# S6E1C1xB register map
Vendor: Cypress; File version: 2.0
CPU: CM0PLUS r0p1, little endian, no MPU, no FPU, 2 interrupt priority bits
Registers are 32-bit, read-write, reset 0x0 unless marked. A register's access mark holds for its fields unless they carry their own. Offsets are from the block's base; [hi:lo] are bit positions; {n}, {i} and the like mark numbered series.

## MFSI2S0 — I2S0 Registers
Base 0x4003CA00
Same registers: MFSI2S1 0x4003CA80
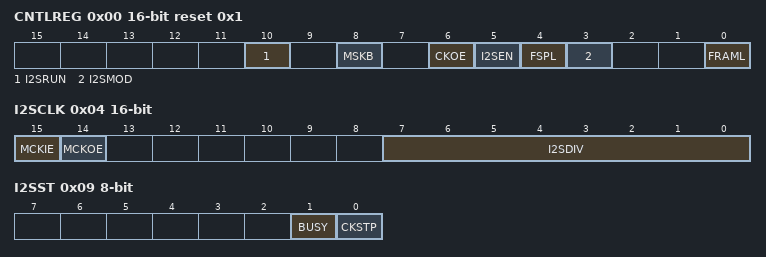
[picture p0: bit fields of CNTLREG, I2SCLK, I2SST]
0x00 CNTLREG 16-bit reset 0x1 — Control Register
  [10] I2SRUN — I2S clock generate enable bit
  [8] MSKB — Mask bit output bit
  [6] CKOE — I2SCK and I2SWS output enable bit
  [5] I2SEN — I2S mode enable bit
  [4] FSPL — I2SWS polarity set bit
  [3] I2SMOD — I2S mode select bit
  [0] FRAML — Frame length select bit
0x04 I2SCLK 16-bit — I2S Clock Register
  [15] MCKIE — Main clock input enable bit
  [14] MCKOE — Main clock output enable bit
  [7:0] I2SDIV — I2S clock division set bit
0x08 I2SRST 8-bit wo — I2S Reset Register
  [7:0] I2SRST — I2S software reset bit
0x09 I2SST 8-bit ro — I2S Status Register
  [1] BUSY — Bus busy indication for transmit bit
  [0] CKSTP — Clock stop indication bit

## DSTC — DSTC registers
Base 0x40061000
0x00 DESTP — Descriptor top address Register
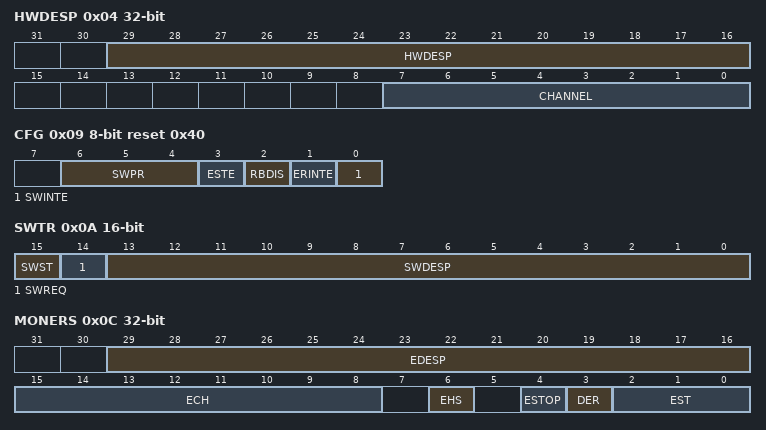
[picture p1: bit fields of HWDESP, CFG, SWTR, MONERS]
0x04 HWDESP — Hardware DES pointer Register
  [29:16] HWDESP, [7:0] CHANNEL
0x08 CMD 8-bit reset 0x1 — Command Register
0x09 CFG 8-bit reset 0x40 — Configuration Register
  [6:4] SWPR — Software transfer priority
  [3] ESTE — Error stop enable
  [2] RBDIS — Read skip buffer disable
  [1] ERINTE — Error interrupt enable
  [0] SWINTE — Software interrupt enable
0x0A SWTR 16-bit — Software trigger Register
  [15] SWST ro — Software status
  [14] SWREQ ro — Software request
  [13:0] SWDESP — Software DES pointer
0x0C MONERS — Transfer Error Status Monitor Register
  [29:16] EDESP ro — Error DES pointer
  [15:8] ECH ro — Error hardware channel
  [6] EHS ro — Error hardware software
  [4] ESTOP ro — Error stop
  [3] DER ro — Double error
  [2:0] EST ro — Error status
0x10 DREQENB0 — DMA request enable Register 0
0x14 DREQENB1 — DMA request enable Register 1
0x30 HWINT0 — Hardware transfer interrupt Register 0
0x34 HWINT1 — Hardware transfer interrupt Register 1
0x50 HWINTCLR0 — Hardware transfer interrupt clear Register 0
0x54 HWINTCLR1 — Hardware transfer interrupt clear Register 1
0x70 DQMSK0 — DMA request mask Register 0
0x74 DQMSK1 — DMA request mask Register 1
0x90 DQMSKCLR0 — DMA request mask clear Register 0
0x94 DQMSKCLR1 — DMA request mask clear Register 1

## MTB_DWT — Micro Trace Buffer Data Watchpoint and Trace Registers
Base 0xF0001000
0x00 CMP_ADDR_START — MTB_DWT Address Compare Start trace Register
  [31:0] ADCMP_STA — MTB_DWT address comparison start trace bits
0x04 CMP_DATA_START — MTB_DWT Data Compare Start trace Register
  [31:0] DTCMP_STA — MTB_DWT data comparison start trace bits
0x08 CMP_MASK_START — MTB_DWT Mask Data Compare Start Trace Register
  [31:0] MSK_STA — MTB_DWT data compare start trace register mask bits
0x10 CMP_ADDR_STOP — MTB_DWT Address Compare Stop trace Register
  [31:0] ADCMP_STO — MTB_DWT address comparison stop trace bits
0x14 CMP_DATA_STOP — MTB_DWT Data Compare Stop trace Register
  [31:0] DTCMP_STO — MTB_DWT data comparison stop trace bits
0x18 CMP_MASK_STOP — MTB_DWT Mask Data Compare Stop Trace Register
  [31:0] MSK_STO — MTB_DWT data compare stop trace register mask bits
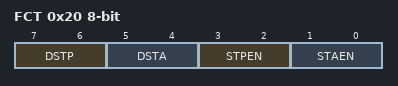
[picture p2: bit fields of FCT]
0x20 FCT 8-bit — MTB_DWT Function Register
  [7:6] DSTP — Data size stop bits
  [5:4] DSTA — Data size start bits
  [3:2] STPEN — Enable MTB_DWT stop MTB function bits
  [1:0] STAEN — Enable MTB_DWT start MTB function bits
{0xFC0+4i} PID{i} ro (i=4..7) — Peripheral ID{i} Register
  [31:0] PERID — Peripheral ID bits
0xFE0 PID0 ro reset 0x16 — Peripheral ID0 Register
  [31:0] PERID — Peripheral ID bits
0xFE4 PID1 ro reset 0x48 — Peripheral ID1 Register
  [31:0] PERID — Peripheral ID bits
0xFE8 PID2 ro reset 0x8 — Peripheral ID2 Register
  [31:0] PERID — Peripheral ID bits
0xFEC PID3 ro — Peripheral ID3 Register
  [31:0] PERID — Peripheral ID bits
0xFF0 CID0 ro reset 0xD — Component ID0 Register
  [31:0] CPNTID — Component ID bits
0xFF4 CID1 ro reset 0x90 — Component ID1 Register
  [31:0] CPNTID — Component ID bits
0xFF8 CID2 ro reset 0x5 — Component ID2 Register
  [31:0] CPNTID — Component ID bits
0xFFC CID3 ro reset 0xB1 — Component ID3 Register
  [31:0] CPNTID — Component ID bits

## FASTIO — Fast GPIO Registers
Base 0xF8000000
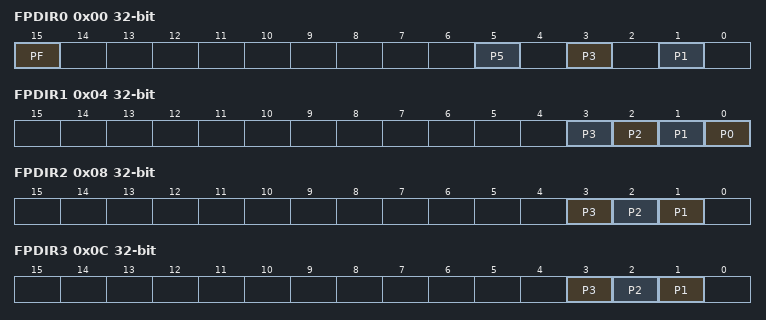
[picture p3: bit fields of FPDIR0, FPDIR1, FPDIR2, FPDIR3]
0x00 FPDIR0 ro — Fast GPIO Input Data Register 0
  [15] PF rw — Bit15 of FPDIR0
  [5] P5 rw — Bit5 of FPDIR0
  [3] P3 rw — Bit3 of FPDIR0
  [1] P1 rw — Bit1 of FPDIR0
0x04 FPDIR1 ro — Fast GPIO Input Data Register 1
  [n] P{n} rw (n=0..3) — Bit{n} of FPDIR1
0x08 FPDIR2 ro — Fast GPIO Input Data Register 2
  [3] P3 rw — Bit3 of FPDIR2
  [2] P2 rw — Bit2 of FPDIR2
  [1] P1 rw — Bit1 of FPDIR2
0x0C FPDIR3 ro — Fast GPIO Input Data Register 3
  [3] P3 rw — Bit3 of FPDIR3
  [2] P2 rw — Bit2 of FPDIR3
  [1] P1 rw — Bit1 of FPDIR3
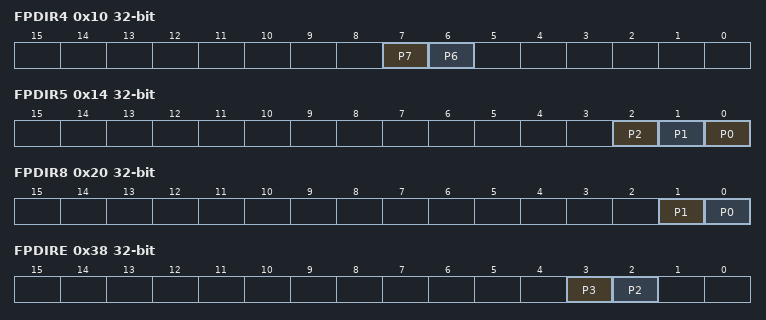
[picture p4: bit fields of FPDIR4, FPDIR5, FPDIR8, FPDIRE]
0x10 FPDIR4 ro — Fast GPIO Input Data Register 4
  [7] P7 rw — Bit7 of FPDIR4
  [6] P6 rw — Bit6 of FPDIR4
0x14 FPDIR5 ro — Fast GPIO Input Data Register 5
  [2] P2 rw — Bit2 of FPDIR5
  [1] P1 rw — Bit1 of FPDIR5
  [0] P0 rw — Bit0 of FPDIR5
0x18 FPDIR6 ro — Fast GPIO Input Data Register 6
  [0] P0 rw — Bit0 of FPDIR6
0x1C FPDIR7 ro reset not defined — Fast GPIO Input Data Register 7
0x20 FPDIR8 ro — Fast GPIO Input Data Register 8
  [1] P1 rw — Bit1 of FPDIR8
  [0] P0 rw — Bit0 of FPDIR8
0x24 FPDIR9 ro reset not defined — Fast GPIO Input Data Register 9
0x28 FPDIRA ro reset not defined — Fast GPIO Input Data Register A
0x2C FPDIRB ro reset not defined — Fast GPIO Input Data Register B
0x30 FPDIRC ro reset not defined — Fast GPIO Input Data Register C
0x34 FPDIRD ro reset not defined — Fast GPIO Input Data Register D
0x38 FPDIRE ro — Fast GPIO Input Data Register E
  [3] P3 rw — Bit3 of FPDIRE
  [2] P2 rw — Bit2 of FPDIRE
0x3C FPDIRF ro reset not defined — Fast GPIO Input Data Register F
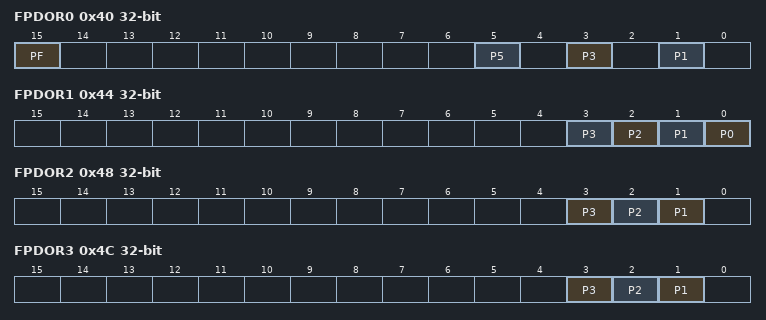
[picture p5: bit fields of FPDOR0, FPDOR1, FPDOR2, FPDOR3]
0x40 FPDOR0 — Fast GPIO Output Data Register 0
  [15] PF — Bit15 of FPDOR0
  [5] P5 — Bit5 of FPDOR0
  [3] P3 — Bit3 of FPDOR0
  [1] P1 — Bit1 of FPDOR0
0x44 FPDOR1 — Fast GPIO Output Data Register 1
  [n] P{n} (n=0..3) — Bit{n} of FPDOR1
0x48 FPDOR2 — Fast GPIO Output Data Register 2
  [3] P3 — Bit3 of FPDOR2
  [2] P2 — Bit2 of FPDOR2
  [1] P1 — Bit1 of FPDOR2
0x4C FPDOR3 — Fast GPIO Output Data Register 3
  [3] P3 — Bit3 of FPDOR3
  [2] P2 — Bit2 of FPDOR3
  [1] P1 — Bit1 of FPDOR3
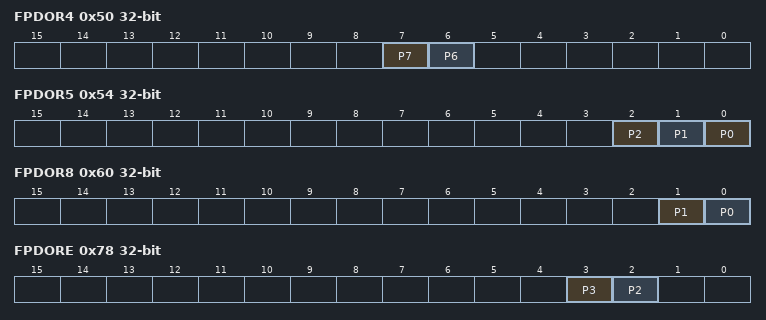
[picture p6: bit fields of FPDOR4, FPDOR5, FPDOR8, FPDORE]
0x50 FPDOR4 — Fast GPIO Output Data Register 4
  [7] P7 — Bit7 of FPDOR4
  [6] P6 — Bit6 of FPDOR4
0x54 FPDOR5 — Fast GPIO Output Data Register 5
  [2] P2 — Bit2 of FPDOR5
  [1] P1 — Bit1 of FPDOR5
  [0] P0 — Bit0 of FPDOR5
0x58 FPDOR6 — Fast GPIO Output Data Register 6
  [0] P0 — Bit0 of FPDOR6
0x5C FPDOR7 reset not defined — Fast GPIO Output Data Register 7
0x60 FPDOR8 — Fast GPIO Output Data Register 8
  [1] P1 — Bit1 of FPDOR8
  [0] P0 — Bit0 of FPDOR8
0x64 FPDOR9 reset not defined — Fast GPIO Output Data Register 9
0x68 FPDORA reset not defined — Fast GPIO Output Data Register A
0x6C FPDORB reset not defined — Fast GPIO Output Data Register B
0x70 FPDORC reset not defined — Fast GPIO Output Data Register C
0x74 FPDORD reset not defined — Fast GPIO Output Data Register D
0x78 FPDORE — Fast GPIO Output Data Register E
  [3] P3 — Bit3 of FPDORE
  [2] P2 — Bit2 of FPDORE
0x7C FPDORF reset not defined — Fast GPIO Output Data Register F
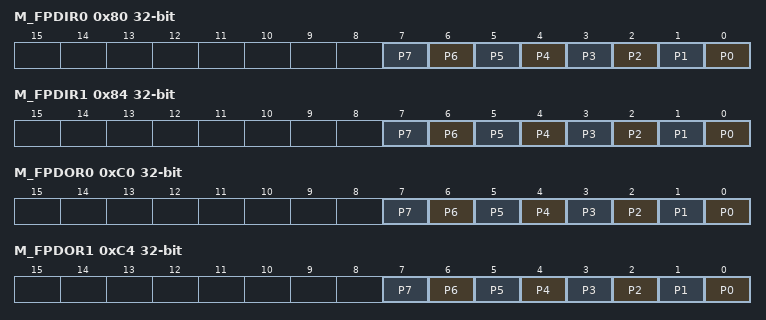
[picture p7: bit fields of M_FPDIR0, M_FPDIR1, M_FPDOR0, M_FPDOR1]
0x80 M_FPDIR0 ro — Mirror Fast GPIO Input Data Register 0
  [n] P{n} rw (n=0..7) — Bit{n} of M_FPDIR0
0x84 M_FPDIR1 ro — Mirror Fast GPIO Input Data Register 1
  [n] P{n} rw (n=0..7) — Bit{n} of M_FPDIR1
0xC0 M_FPDOR0 — Mirror Fast GPIO Output Data Register 0
  [n] P{n} (n=0..7) — Bit{n} of M_FPDOR0
0xC4 M_FPDOR1 — Mirror Fast GPIO Output Data Register 1
  [n] P{n} (n=0..7) — Bit{n} of M_FPDOR1

## VIR — Vector Indicate Registers
Base 0xF8000100
{0x0+4i} VIR{i:02} ro (i=0..31) — Vector Indicate Register {i:02}
